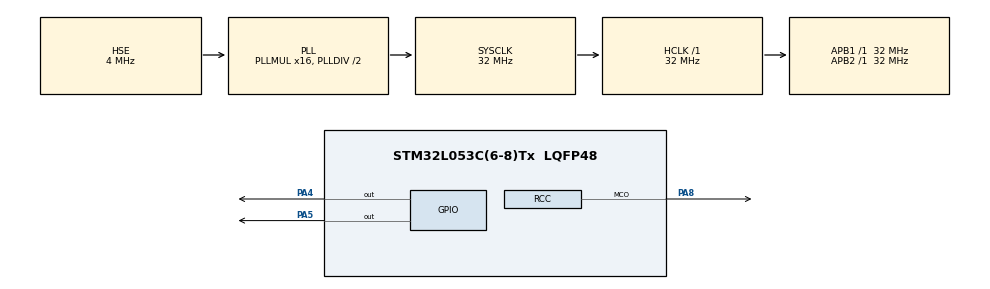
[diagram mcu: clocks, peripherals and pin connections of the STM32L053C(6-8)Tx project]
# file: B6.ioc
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Mcu.Family=STM32L0
Mcu.Name=STM32L053C(6-8)Tx
Mcu.Package=LQFP48
PA4.GPIO_Speed=GPIO_SPEED_FREQ_VERY_HIGH
PA4.Signal=GPIO_Output
PA5.GPIO_Speed=GPIO_SPEED_FREQ_VERY_HIGH
PA5.Signal=GPIO_Output
PA8.Mode=Clock-out
PA8.Signal=RCC_MCO
PH0-OSC_IN.Mode=HSE-External-Oscillator
PH0-OSC_IN.Signal=RCC_OSC_IN
PH1-OSC_OUT.Mode=HSE-External-Oscillator
PH1-OSC_OUT.Signal=RCC_OSC_OUT
ProjectManager.HeapSize=0x200
ProjectManager.StackSize=0x400
ProjectManager.TargetToolchain=Makefile
RCC.AHBFreq_Value=32000000
RCC.APB1Freq_Value=32000000
RCC.APB1TimFreq_Value=32000000
RCC.APB2Freq_Value=32000000
RCC.APB2TimFreq_Value=32000000
RCC.HCLKFreq_Value=32000000
RCC.HSE_VALUE=4000000
RCC.HSI16_VALUE=16000000
RCC.HSI48_VALUE=48000000
RCC.HSI_VALUE=16000000
RCC.LSE_VALUE=32768
RCC.MSI_VALUE=2097000
RCC.PLLMUL=RCC_PLLMUL_16
RCC.PLLSourceVirtual=RCC_PLLSOURCE_HSE
RCC.RCC_MCODiv=RCC_MCODIV_16
RCC.RCC_MCOSource=RCC_MCO1SOURCE_PLLCLK
RCC.SYSCLKFreq_VALUE=32000000
RCC.SYSCLKSource=RCC_SYSCLKSOURCE_PLLCLK
RCC.VCOOutputFreq_Value=64000000
board=custom

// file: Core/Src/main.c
/* USER CODE BEGIN Header */
/**
  ******************************************************************************
  * @file           : main.c
  * @brief          : Main program body
  ******************************************************************************
  * @attention
  *
  * Copyright (c) 2023 STMicroelectronics.
  * All rights reserved.
  *
  * This software is licensed under terms that can be found in the LICENSE file
  * in the root directory of this software component.
  * If no LICENSE file comes with this software, it is provided AS-IS.
  *
  ******************************************************************************
  */
/* USER CODE END Header */
#include "main.h"
#include "gpio.h"

void SystemClock_Config(void);

int main(void)
{

  /* MCU Configuration--------------------------------------------------------*/

  /* Reset of all peripherals, Initializes the Flash interface and the Systick. */
  HAL_Init();

  /* Configure the system clock */
  SystemClock_Config();

  /* Initialize all configured peripherals */
  MX_GPIO_Init();
  /* USER CODE BEGIN 2 */
  HAL_GPIO_WritePin(GPIOA,GPIO_PIN_4,GPIO_PIN_SET);
  /* USER CODE END 2 */

  /* Infinite loop */
  /* USER CODE BEGIN WHILE */
  while (1)
  {
    /// A3 Egen toggling
    //GPIOA->ODR ^= (1 << 5);
    LL_GPIO_SetOutputPin(GPIOA,GPIO_PIN_5);
    LL_GPIO_ResetOutputPin(GPIOA,GPIO_PIN_5);
    //LL_GPIO_TogglePin(GPIOA,GPIO_PIN_5);
    //HAL_GPIO_TogglePin(GPIOA,GPIO_PIN_5);
    ///

    // HAL TOggling
    //HAL_GPIO_TogglePin(GPIOA,GPIO_PIN_4);

    /* USER CODE END WHILE */

  }
}

void SystemClock_Config(void)
{
  RCC_OscInitTypeDef RCC_OscInitStruct = {0};
  RCC_ClkInitTypeDef RCC_ClkInitStruct = {0};

  /** Configure the main internal regulator output voltage
  */
  __HAL_PWR_VOLTAGESCALING_CONFIG(PWR_REGULATOR_VOLTAGE_SCALE1);

  /** Initializes the RCC Oscillators according to the specified parameters
  * in the RCC_OscInitTypeDef structure.
  */
  RCC_OscInitStruct.OscillatorType = RCC_OSCILLATORTYPE_HSE;
  RCC_OscInitStruct.HSEState = RCC_HSE_ON;
  RCC_OscInitStruct.PLL.PLLState = RCC_PLL_ON;
  RCC_OscInitStruct.PLL.PLLSource = RCC_PLLSOURCE_HSE;
  RCC_OscInitStruct.PLL.PLLMUL = RCC_PLLMUL_16;
  RCC_OscInitStruct.PLL.PLLDIV = RCC_PLLDIV_2;
  if (HAL_RCC_OscConfig(&RCC_OscInitStruct) != HAL_OK)
  {
    Error_Handler();
  }

  /** Initializes the CPU, AHB and APB buses clocks
  */
  RCC_ClkInitStruct.ClockType = RCC_CLOCKTYPE_HCLK|RCC_CLOCKTYPE_SYSCLK
                              |RCC_CLOCKTYPE_PCLK1|RCC_CLOCKTYPE_PCLK2;
  RCC_ClkInitStruct.SYSCLKSource = RCC_SYSCLKSOURCE_PLLCLK;
  RCC_ClkInitStruct.AHBCLKDivider = RCC_SYSCLK_DIV1;
  RCC_ClkInitStruct.APB1CLKDivider = RCC_HCLK_DIV1;
  RCC_ClkInitStruct.APB2CLKDivider = RCC_HCLK_DIV1;

  if (HAL_RCC_ClockConfig(&RCC_ClkInitStruct, FLASH_LATENCY_1) != HAL_OK)
  {
    Error_Handler();
  }
  HAL_RCC_MCOConfig(RCC_MCO1, RCC_MCO1SOURCE_PLLCLK, RCC_MCODIV_16);
}

void Error_Handler(void)
{
  __disable_irq();
  while (1)
  {
  }
}
